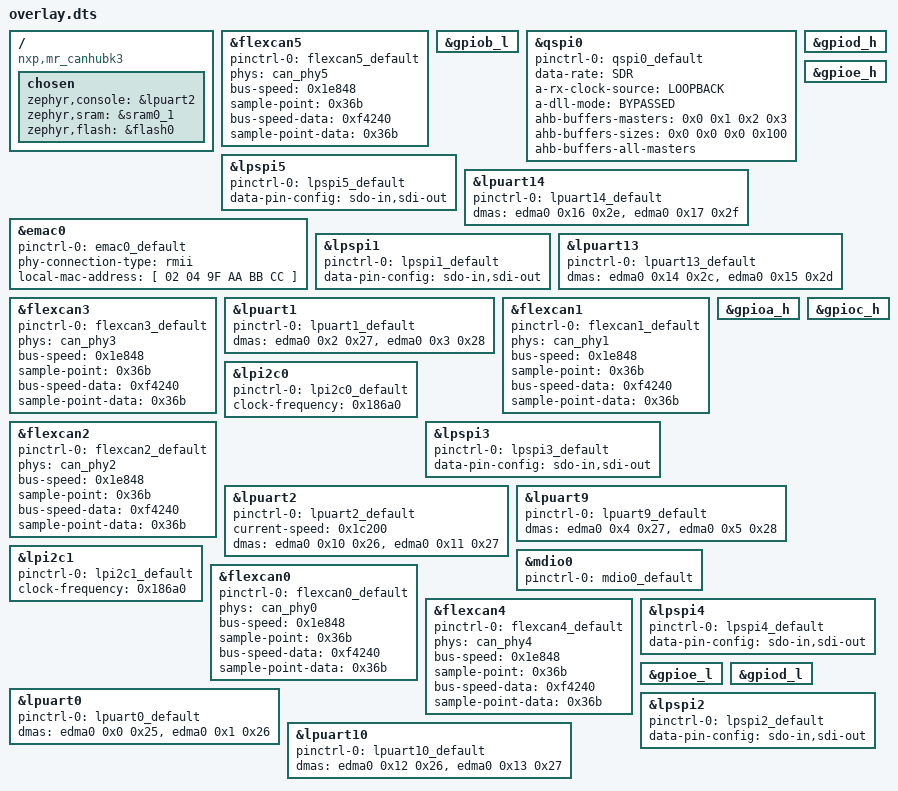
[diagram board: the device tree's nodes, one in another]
/ {
	compatible = "nxp,mr_canhubk3";
	chosen {
		zephyr,console = &lpuart2;
		zephyr,sram = &sram0_1;
		zephyr,flash = &flash0;
	};
};
&flexcan5{
	pinctrl-0 = < &flexcan5_default >;
	pinctrl-names = "default";
	phys = < &can_phy5 >;
	bus-speed = < 0x1e848 >;
	sample-point = < 0x36b >;
	bus-speed-data = < 0xf4240 >;
	sample-point-data = < 0x36b >;
};
&gpiob_l{
	status = "okay";
};
&qspi0{
	status = "okay";
	pinctrl-0 = < &qspi0_default >;
	pinctrl-names = "default";
	data-rate = "SDR";
	a-rx-clock-source = "LOOPBACK";
	a-dll-mode = "BYPASSED";
	ahb-buffers-masters = < 0x0 0x1 0x2 0x3 >;
	ahb-buffers-sizes = < 0x0 0x0 0x0 0x100 >;
	ahb-buffers-all-masters;
};
&lpspi5{
	pinctrl-0 = < &lpspi5_default >;
	pinctrl-names = "default";
	data-pin-config = "sdo-in,sdi-out";
};
&gpiod_h{
	status = "okay";
};
&lpuart14{
	pinctrl-0 = < &lpuart14_default >;
	pinctrl-names = "default";
	dmas = < &edma0 0x16 0x2e >, < &edma0 0x17 0x2f >;
	dma-names = "tx", "rx";
};
&gpioe_h{
	status = "okay";
};
&emac0{
	status = "okay";
	pinctrl-0 = < &emac0_default >;
	pinctrl-names = "default";
	phy-connection-type = "rmii";
	local-mac-address = [ 02 04 9F AA BB CC ];
};
&lpspi1{
	pinctrl-0 = < &lpspi1_default >;
	pinctrl-names = "default";
	data-pin-config = "sdo-in,sdi-out";
};
&lpuart13{
	pinctrl-0 = < &lpuart13_default >;
	pinctrl-names = "default";
	dmas = < &edma0 0x14 0x2c >, < &edma0 0x15 0x2d >;
	dma-names = "tx", "rx";
};
&flexcan3{
	pinctrl-0 = < &flexcan3_default >;
	pinctrl-names = "default";
	phys = < &can_phy3 >;
	bus-speed = < 0x1e848 >;
	sample-point = < 0x36b >;
	bus-speed-data = < 0xf4240 >;
	sample-point-data = < 0x36b >;
};
&lpuart1{
	pinctrl-0 = < &lpuart1_default >;
	pinctrl-names = "default";
	dmas = < &edma0 0x2 0x27 >, < &edma0 0x3 0x28 >;
	dma-names = "tx", "rx";
};
&flexcan1{
	pinctrl-0 = < &flexcan1_default >;
	pinctrl-names = "default";
	phys = < &can_phy1 >;
	bus-speed = < 0x1e848 >;
	sample-point = < 0x36b >;
	bus-speed-data = < 0xf4240 >;
	sample-point-data = < 0x36b >;
};
&lpi2c0{
	pinctrl-0 = < &lpi2c0_default >;
	pinctrl-names = "default";
	clock-frequency = < 0x186a0 >;
};
&flexcan2{
	pinctrl-0 = < &flexcan2_default >;
	pinctrl-names = "default";
	phys = < &can_phy2 >;
	bus-speed = < 0x1e848 >;
	sample-point = < 0x36b >;
	bus-speed-data = < 0xf4240 >;
	sample-point-data = < 0x36b >;
};
&gpioa_h{
	status = "okay";
};
&lpspi3{
	status = "okay";
	pinctrl-0 = < &lpspi3_default >;
	pinctrl-names = "default";
	data-pin-config = "sdo-in,sdi-out";
};
&lpuart2{
	status = "okay";
	pinctrl-0 = < &lpuart2_default >;
	pinctrl-names = "default";
	current-speed = < 0x1c200 >;
	dmas = < &edma0 0x10 0x26 >, < &edma0 0x11 0x27 >;
	dma-names = "tx", "rx";
};
&lpuart9{
	pinctrl-0 = < &lpuart9_default >;
	pinctrl-names = "default";
	dmas = < &edma0 0x4 0x27 >, < &edma0 0x5 0x28 >;
	dma-names = "tx", "rx";
};
&lpi2c1{
	pinctrl-0 = < &lpi2c1_default >;
	pinctrl-names = "default";
	clock-frequency = < 0x186a0 >;
};
&mdio0{
	status = "okay";
	pinctrl-0 = < &mdio0_default >;
	pinctrl-names = "default";
};
&flexcan0{
	status = "okay";
	pinctrl-0 = < &flexcan0_default >;
	pinctrl-names = "default";
	phys = < &can_phy0 >;
	bus-speed = < 0x1e848 >;
	sample-point = < 0x36b >;
	bus-speed-data = < 0xf4240 >;
	sample-point-data = < 0x36b >;
};
&gpioc_h{
	status = "okay";
};
&flexcan4{
	pinctrl-0 = < &flexcan4_default >;
	pinctrl-names = "default";
	phys = < &can_phy4 >;
	bus-speed = < 0x1e848 >;
	sample-point = < 0x36b >;
	bus-speed-data = < 0xf4240 >;
	sample-point-data = < 0x36b >;
};
&lpuart0{
	pinctrl-0 = < &lpuart0_default >;
	pinctrl-names = "default";
	dmas = < &edma0 0x0 0x25 >, < &edma0 0x1 0x26 >;
	dma-names = "tx", "rx";
};
&lpspi4{
	pinctrl-0 = < &lpspi4_default >;
	pinctrl-names = "default";
	data-pin-config = "sdo-in,sdi-out";
};
&gpioe_l{
	status = "okay";
};
&gpiod_l{
	status = "okay";
};
&lpspi2{
	pinctrl-0 = < &lpspi2_default >;
	pinctrl-names = "default";
	data-pin-config = "sdo-in,sdi-out";
};
&lpuart10{
	pinctrl-0 = < &lpuart10_default >;
	pinctrl-names = "default";
	dmas = < &edma0 0x12 0x26 >, < &edma0 0x13 0x27 >;
	dma-names = "tx", "rx";
};
